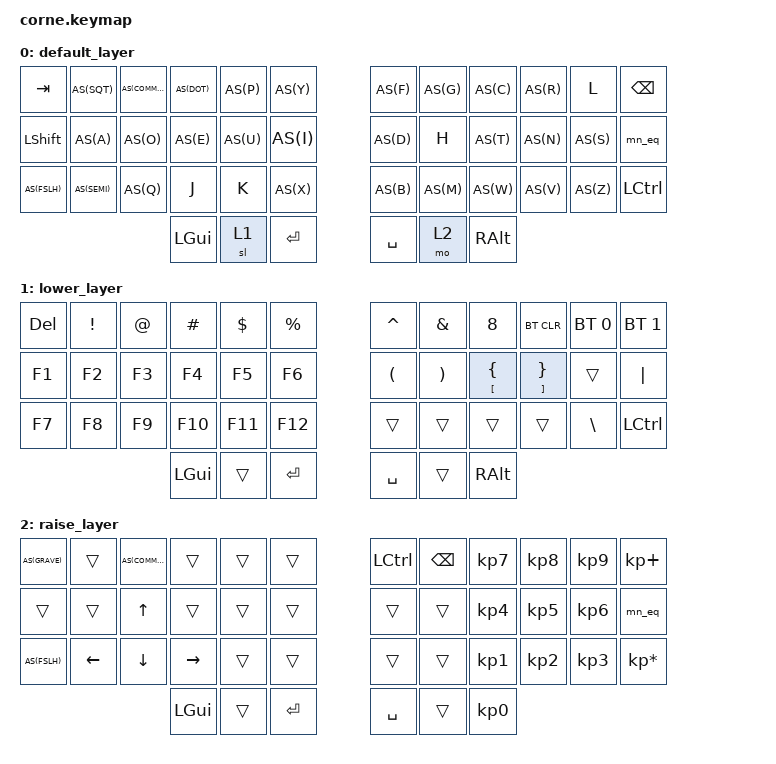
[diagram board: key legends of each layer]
/*
 * Copyright (c) 2020 The ZMK Contributors
 *
 * SPDX-License-Identifier: MIT
 */

#include <behaviors.dtsi>
#include <dt-bindings/zmk/keys.h>
#include <dt-bindings/zmk/bt.h>

#define AS(keycode) &as LS(keycode) keycode     // Autoshift Macro
#define TAP_SPEED 130


/ {    
    combos {
        compatible = "zmk,combos";
        combo_esc: combo_esc {
            timeout-ms = <50>; // Adjust timeout as needed
            key-positions = <1 2>;
            bindings = <&kp ESC>;
        };
    }; 

    behaviors {
        as: auto_shift {
            compatible = "zmk,behavior-hold-tap";
            label = "AUTO_SHIFT";
            #binding-cells = <2>;
            tapping-term-ms = <TAP_SPEED>;
            quick-tap-ms = <0>;
            flavor = "tap-preferred";
            bindings = <&kp>, <&kp>;
        };

        dht: default_hold_tap {
            compatible = "zmk,behavior-hold-tap";
            label = "DEFAULT_HOLD_TAP";
            #binding-cells = <2>;
            tapping-term-ms = <TAP_SPEED>; // You can adjust this as per your liking
            flavor = "tap-preferred"; // prioritize the tap behavior
            bindings = <&kp>, <&kp>;
        };

        mn_eq: minus_equal {
            compatible = "zmk,behavior-tap-dance";
            label = "MINUS_EQUAL";
            #binding-cells = <0>;
            tapping-term-ms = <TAP_SPEED>; // adjust this as per your liking
            bindings = <&kp MINUS>, <&kp UNDER>, <&kp EQUAL>;
        };

        td00: tap_dance_tab_esc {
            compatible = "zmk,behavior-tap-dance";
            label = "TAP_DANCE_TAB_ESC"; 
            #binding-cells = <0>; 
            tapping-term-ms = <TAP_SPEED>; 
            bindings = <&kp TAB>, <&kp ESC>;
        }; 

        td02: tap_dance_ctrl {
            compatible = "zmk,behavior-tap-dance";
            label = "TAP_DANCE_CTRL";
            #binding-cells = <0>;
            tapping-term-ms = <TAP_SPEED>;
            bindings = <&kp LCTRL>, <&kp LGUI>;
        };

    };    
    

    keymap {
        compatible = "zmk,keymap";
            default_layer {
// ----------------------------------------------------------------------------------------------------------------------------------------------------------
// |---------ESCAPE---------|
// |  TAB       |  '        |  ,        |  .        |  P        |  Y        |       |  F        |  G        |  C        |  R        |  L        | BKSP      |
// |  SHIFT     |  A        |  O        |  E        |  U        |  I        |       |  D        |  H        |  T        |  N        |  S        |  - _ =    |
// | /:?        |  ;        |  Q        |  J        |  K        |  X        |       |  B        |  M        |  W        |  V        |  Z        | ESC       |
//                                      | GUI       | LWR       | RET       |       | SPACE     | RSE       | ALT       |
    //&td00       AS(SQT)     AS(COMMA)   AS(DOT)     AS(P)       AS(Y)               AS(F)       AS(G)       AS(C)       AS(R)       &kp L       &kp BSPC

                bindings = <
    &kp TAB     AS(SQT)     AS(COMMA)   AS(DOT)     AS(P)       AS(Y)               AS(F)       AS(G)       AS(C)       AS(R)       &kp L       &kp BSPC
    &kp LSHFT   AS(A)       AS(O)       AS(E)       AS(U)       AS(I)               AS(D)       &kp H       AS(T)       AS(N)       AS(S)       &mn_eq
    AS(FSLH)    AS(SEMI)    AS(Q)       &kp J       &kp K       AS(X)               AS(B)       AS(M)       AS(W)       AS(V)       AS(Z)       &kp LCTRL
                                        &kp LGUI    &sl 1       &kp RET             &kp SPACE   &mo 2      &kp RALT
        >;
    };

    lower_layer {
// ----------------------------------------------------------------------------------------------------------------------------------------------------------------------
// | DEl        |  !        |  @        |  #        |  $        |  %        |       |  ^        |  &        |  *                |  BTCR         |  BT1      | BT2       |
// | F1         | F2        | F3        | F4        | F5        | F6        |       | LFT       | DWN       |  UP               | RGT           |           | PIPE      |
// | F7         | F8        | F9        | F10       | F11       | F12       |       |           |           |                   |               |           |           |
//                                      | GUI       |           | RET       |       | SPACE     |           | ALT               |
//    &kp F1       &kp F2      &kp F3      &kp F4      &kp F5      &kp F6              &kp LPAR    &kp RPAR    &lb_br      &rb_br      &trans       &kp PIPE
                        bindings = <
    &kp DEL      &kp EXCL    &kp AT      &kp HASH    &kp DLLR    &kp PRCNT           &kp CARET   &kp AMPS    &kp N8              &bt BT_CLR      &bt BT_SEL 0 &bt BT_SEL 1
    &kp F1       &kp F2      &kp F3      &kp F4      &kp F5      &kp F6              &kp LPAR    &kp RPAR    &dht LBKT LBRC      &dht RBKT RBRC  &trans       &kp PIPE
    &kp F7       &kp F8      &kp F9      &kp F10     &kp F11     &kp F12             &trans      &trans      &trans              &trans          &kp BSLH     &kp LCTRL
                                        &kp LGUI    &trans      &kp RET             &kp SPACE   &trans      &kp RALT
        >;
    };


    raise_layer {
// -----------------------------------------------------------------------------------------
// | GRAVE      |           | ,         |           |           |           |       |           |           |           |           |           |           |
// |            |           | UP        |           |           |           |       |           |           |           |           |           |           |
// |            | LEFT      | DOWN      | RIGHT     |           |           |       |           |           |           |           |           |           |
//                                      | GUI       |           | RET       |       | SPACE     |           | ALT       |
                        bindings = <
    AS(GRAVE)   &trans      AS(COMMA)   &trans      &trans      &trans              &kp LCTRL   &kp BSPC    &kp KP_N7   &kp KP_N8   &kp KP_N9    &kp KP_PLUS
    &trans      &trans      &kp UP      &trans      &trans      &trans              &trans      &trans      &kp KP_N4   &kp KP_N5   &kp KP_N6    &mn_eq
    AS(FSLH)    &kp LEFT    &kp DOWN    &kp RIGHT   &trans      &trans              &trans      &trans      &kp KP_N1   &kp KP_N2   &kp KP_N3    &kp KP_ASTERISK
                                        &kp LGUI    &trans      &kp RET             &kp SPACE   &trans      &kp KP_N0
                        >;
                };
        };
};

//                 // blank layer template
//                 new_layer {
// // -----------------------------------------------------------------------------------------
// // |            |           |           |           |           |           |       |           |           |           |           |           |           |
// // |            |           |           |           |           |           |       |           |           |           |           |           |           |
// // |            |           |           |           |           |           |       |           |           |           |           |           |           |
// //                                      | GUI       |           | RET       |       | SPACE     |           | ALT       |
//                         bindings = <
//     &trans      &trans      &trans      &trans      &trans      &trans              &trans      &trans      &trans      &trans      &trans      &trans
//     &trans      &trans      &trans      &trans      &trans      &trans              &trans      &trans      &trans      &trans      &trans      &trans
//     &trans      &trans      &trans      &trans      &trans      &trans              &trans      &trans      &trans      &trans      &trans      &trans
//                                         &kp LGUI    &trans      &kp RET             &kp SPACE   &trans      &kp RALT
//                         >;
//                 };
//         };
// };
